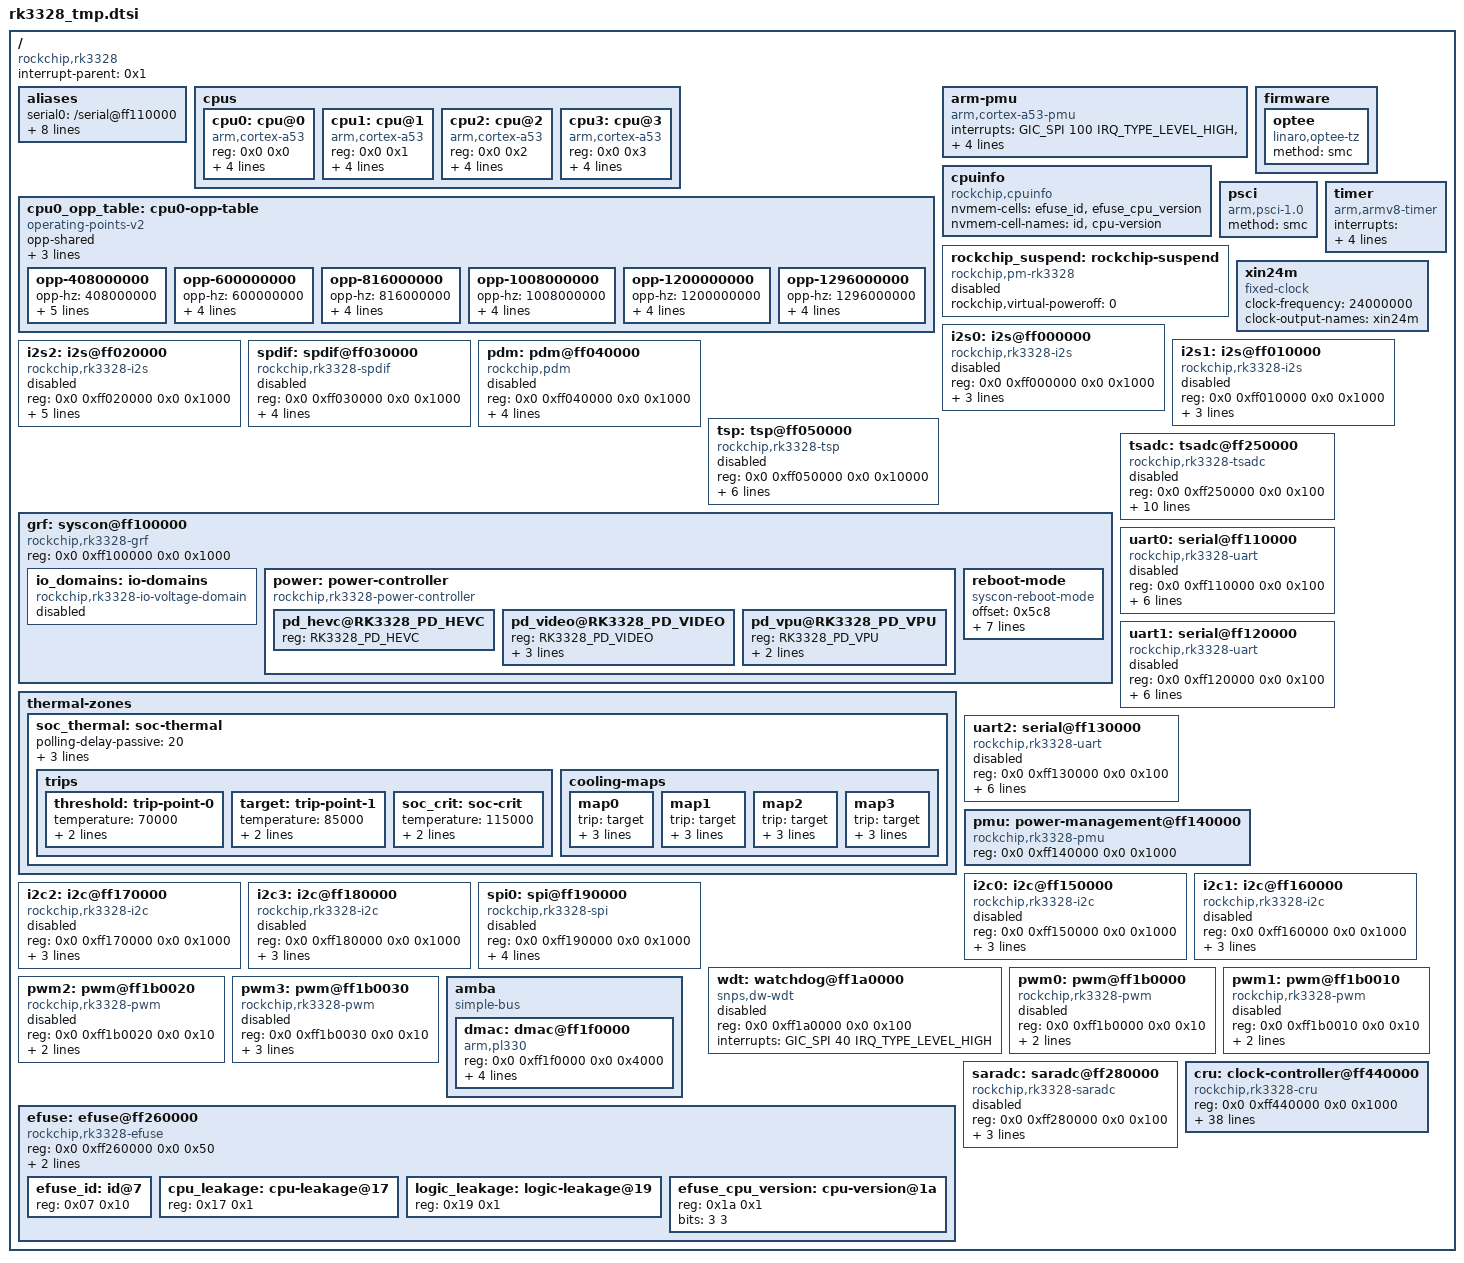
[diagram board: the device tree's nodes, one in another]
/*
 * Copyright (c) 2016 Fuzhou Rockchip Electronics Co., Ltd
 *
 * This file is dual-licensed: you can use it either under the terms
 * of the GPL or the X11 license, at your option. Note that this dual
 * licensing only applies to this file, and not this project as a
 * whole.
 *
 *  a) This library is free software; you can redistribute it and/or
 *     modify it under the terms of the GNU General Public License as
 *     published by the Free Software Foundation; either version 2 of the
 *     License, or (at your option) any later version.
 *
 *     This library is distributed in the hope that it will be useful,
 *     but WITHOUT ANY WARRANTY; without even the implied warranty of
 *     MERCHANTABILITY or FITNESS FOR A PARTICULAR PURPOSE.  See the
 *     GNU General Public License for more details.
 *
 * Or, alternatively,
 *
 *  b) Permission is hereby granted, free of charge, to any person
 *     obtaining a copy of this software and associated documentation
 *     files (the "Software"), to deal in the Software without
 *     restriction, including without limitation the rights to use,
 *     copy, modify, merge, publish, distribute, sublicense, and/or
 *     sell copies of the Software, and to permit persons to whom the
 *     Software is furnished to do so, subject to the following
 *     conditions:
 *
 *     The above copyright notice and this permission notice shall be
 *     included in all copies or substantial portions of the Software.
 *
 *     THE SOFTWARE IS PROVIDED "AS IS", WITHOUT WARRANTY OF ANY KIND,
 *     EXPRESS OR IMPLIED, INCLUDING BUT NOT LIMITED TO THE WARRANTIES
 *     OF MERCHANTABILITY, FITNESS FOR A PARTICULAR PURPOSE AND
 *     NONINFRINGEMENT. IN NO EVENT SHALL THE AUTHORS OR COPYRIGHT
 *     HOLDERS BE LIABLE FOR ANY CLAIM, DAMAGES OR OTHER LIABILITY,
 *     WHETHER IN AN ACTION OF CONTRACT, TORT OR OTHERWISE, ARISING
 *     FROM, OUT OF OR IN CONNECTION WITH THE SOFTWARE OR THE USE OR
 *     OTHER DEALINGS IN THE SOFTWARE.
 */

#include <dt-bindings/clock/rk3328-cru.h>
#include <dt-bindings/gpio/gpio.h>
#include <dt-bindings/interrupt-controller/arm-gic.h>
#include <dt-bindings/interrupt-controller/irq.h>
#include <dt-bindings/pinctrl/rockchip.h>
#include <dt-bindings/soc/rockchip,boot-mode.h>
#include <dt-bindings/soc/rockchip-system-status.h>
#include <dt-bindings/power/rk3328-power.h>
#include <dt-bindings/thermal/thermal.h>
#include "rk3328-dram-default-timing.dtsi"

/ {
	compatible = "rockchip,rk3328";

	interrupt-parent = <0x1>;	//<&gic>;
	#address-cells = <2>;
	#size-cells = <2>;

	aliases {
		serial0 = "/serial@ff110000";		//&uart0;
		serial1 = "/serial@ff120000";		//&uart1;
		serial2 = "/serial@ff130000";		//&uart2;
		i2c0 = "/i2c@ff150000";			//&i2c0;
		i2c1 = "/i2c@ff160000";			//&i2c1;
		i2c2 = "/i2c@ff170000";			//&i2c2;
		i2c3 = "/i2c@ff180000";			//&i2c3;
		ethernet0 = "/ethernet@ff540000";	//&gmac2io;
		ethernet1 = "/ethernet@ff550000";	//&gmac2phy;
	};

	cpus {
		#address-cells = <2>;
		#size-cells = <0>;

		cpu0: cpu@0 {
			device_type = "cpu";
			compatible = "arm,cortex-a53", "arm,armv8";
			reg = <0x0 0x0>;
			enable-method = "psci";
			clocks = <&cru ARMCLK>;
			#cooling-cells = <2>; /* min followed by max */
			dynamic-power-coefficient = <120>;
			operating-points-v2 = <&cpu0_opp_table>;
		};
		cpu1: cpu@1 {
			device_type = "cpu";
			compatible = "arm,cortex-a53", "arm,armv8";
			reg = <0x0 0x1>;
			clocks = <&cru ARMCLK>;
			dynamic-power-coefficient = <120>;
			enable-method = "psci";
			operating-points-v2 = <&cpu0_opp_table>;
		};
		cpu2: cpu@2 {
			device_type = "cpu";
			compatible = "arm,cortex-a53", "arm,armv8";
			reg = <0x0 0x2>;
			clocks = <&cru ARMCLK>;
			dynamic-power-coefficient = <120>;
			enable-method = "psci";
			operating-points-v2 = <&cpu0_opp_table>;
		};
		cpu3: cpu@3 {
			device_type = "cpu";
			compatible = "arm,cortex-a53", "arm,armv8";
			reg = <0x0 0x3>;
			clocks = <&cru ARMCLK>;
			dynamic-power-coefficient = <120>;
			enable-method = "psci";
			operating-points-v2 = <&cpu0_opp_table>;
		};
	};
	
	cpu0_opp_table: cpu0-opp-table {
		compatible = "operating-points-v2";
		opp-shared;

		rockchip,leakage-voltage-sel = <
			1   10    0
			11  254   1
		>;
		nvmem-cells = <&cpu_leakage>;
		nvmem-cell-names = "cpu_leakage";

		opp-408000000 {
			opp-hz = /bits/ 64 <408000000>;
			opp-microvolt = <950000 950000 1350000>;
			opp-microvolt-L0 = <950000 950000 1350000>;
			opp-microvolt-L1 = <950000 950000 1350000>;
			clock-latency-ns = <40000>;
			opp-suspend;
		};
		opp-600000000 {
			opp-hz = /bits/ 64 <600000000>;
			opp-microvolt = <950000 950000 1350000>;
			opp-microvolt-L0 = <950000 950000 1350000>;
			opp-microvolt-L1 = <950000 950000 1350000>;
			clock-latency-ns = <40000>;
		};
		opp-816000000 {
			opp-hz = /bits/ 64 <816000000>;
			opp-microvolt = <1050000 1050000 1350000>;
			opp-microvolt-L0 = <1050000 1050000 1350000>;
			opp-microvolt-L1 = <1000000 1000000 1350000>;
			clock-latency-ns = <40000>;
		};
		opp-1008000000 {
			opp-hz = /bits/ 64 <1008000000>;
			opp-microvolt = <1150000 1150000 1350000>;
			opp-microvolt-L0 = <1150000 1150000 1350000>;
			opp-microvolt-L1 = <1100000 1100000 1350000>;
			clock-latency-ns = <40000>;
		};
		opp-1200000000 {
			opp-hz = /bits/ 64 <1200000000>;
			opp-microvolt = <1275000 1275000 1350000>;
			opp-microvolt-L0 = <1275000 1275000 1350000>;
			opp-microvolt-L1 = <1225000 1225000 1350000>;
			clock-latency-ns = <40000>;
		};
		opp-1296000000 {
			opp-hz = /bits/ 64 <1296000000>;
			opp-microvolt = <1350000 1350000 1350000>;
			opp-microvolt-L0 = <1350000 1350000 1350000>;
			opp-microvolt-L1 = <1300000 1300000 1350000>;
			clock-latency-ns = <40000>;
		};
		/*
		opp-1392000000 {
			opp-hz = /bits/ 64 <1392000000>;
			opp-microvolt = <1350000 1350000 1350000>;
			opp-microvolt-L0 = <1350000 1350000 1350000>;
			opp-microvolt-L1 = <1325000 1325000 1350000>;
			clock-latency-ns = <40000>;
		};
		opp-1512000000 {
			opp-hz = /bits/ 64 <1512000000>;
			opp-microvolt = <1350000 1350000 1350000>;
			opp-microvolt-L0 = <1350000 1350000 1350000>;
			opp-microvolt-L1 = <1325000 1325000 1350000>;
			clock-latency-ns = <40000>;
		};
		*/
	};
	
	arm-pmu {
		compatible = "arm,cortex-a53-pmu";
		interrupts = <GIC_SPI 100 IRQ_TYPE_LEVEL_HIGH>,
			     <GIC_SPI 101 IRQ_TYPE_LEVEL_HIGH>,
			     <GIC_SPI 102 IRQ_TYPE_LEVEL_HIGH>,
			     <GIC_SPI 103 IRQ_TYPE_LEVEL_HIGH>;
		interrupt-affinity = <&cpu0>, <&cpu1>, <&cpu2>, <&cpu3>;
	};

	cpuinfo {
		compatible = "rockchip,cpuinfo";
		nvmem-cells = <&efuse_id>, <&efuse_cpu_version>;
		nvmem-cell-names = "id", "cpu-version";
	};

	firmware {
		optee {
			compatible = "linaro,optee-tz";
			method = "smc";
		};
	};

	psci {
		compatible = "arm,psci-1.0";
		method = "smc";
	};

	rockchip_suspend: rockchip-suspend {
		compatible = "rockchip,pm-rk3328";
		status = "disabled";
		rockchip,virtual-poweroff = <0>;
	};

	timer {
		compatible = "arm,armv8-timer";
		interrupts = <GIC_PPI 13 (GIC_CPU_MASK_SIMPLE(4) | IRQ_TYPE_LEVEL_LOW)>,
			     <GIC_PPI 14 (GIC_CPU_MASK_SIMPLE(4) | IRQ_TYPE_LEVEL_LOW)>,
			     <GIC_PPI 11 (GIC_CPU_MASK_SIMPLE(4) | IRQ_TYPE_LEVEL_LOW)>,
			     <GIC_PPI 10 (GIC_CPU_MASK_SIMPLE(4) | IRQ_TYPE_LEVEL_LOW)>;
	};

	xin24m: xin24m {
		compatible = "fixed-clock";
		#clock-cells = <0>;
		clock-frequency = <24000000>;
		clock-output-names = "xin24m";
	};

	i2s0: i2s@ff000000 {
		compatible = "rockchip,rk3328-i2s", "rockchip,rk3066-i2s";
		reg = <0x0 0xff000000 0x0 0x1000>;
		interrupts = <GIC_SPI 26 IRQ_TYPE_LEVEL_HIGH>;
		clocks = <&cru SCLK_I2S0>, <&cru HCLK_I2S0_8CH>;
		clock-names = "i2s_clk", "i2s_hclk";
		dmas = <&dmac 11>, <&dmac 12>;
		dma-names = "tx", "rx";
		status = "disabled";
	};

	i2s1: i2s@ff010000 {
		compatible = "rockchip,rk3328-i2s", "rockchip,rk3066-i2s";
		reg = <0x0 0xff010000 0x0 0x1000>;
		interrupts = <GIC_SPI 27 IRQ_TYPE_LEVEL_HIGH>;
		clocks = <&cru SCLK_I2S1>, <&cru HCLK_I2S1_8CH>;
		clock-names = "i2s_clk", "i2s_hclk";
		dmas = <&dmac 14>, <&dmac 15>;
		dma-names = "tx", "rx";
		status = "disabled";
	};

	i2s2: i2s@ff020000 {
		compatible = "rockchip,rk3328-i2s", "rockchip,rk3066-i2s";
		reg = <0x0 0xff020000 0x0 0x1000>;
		interrupts = <GIC_SPI 28 IRQ_TYPE_LEVEL_HIGH>;
		clocks = <&cru SCLK_I2S2>, <&cru HCLK_I2S2_2CH>;
		clock-names = "i2s_clk", "i2s_hclk";
		dmas = <&dmac 0>, <&dmac 1>;
		dma-names = "tx", "rx";
		pinctrl-names = "default", "sleep";
		pinctrl-0 = <0xd 0xe 0xf 0x10 0x11 0x12>;	/*<&i2s2m0_mclk
			     &i2s2m0_sclk
			     &i2s2m0_lrcktx
			     &i2s2m0_lrckrx
			     &i2s2m0_sdo
			     &i2s2m0_sdi>;*/
		pinctrl-1 = <0x13>;				//<&i2s2m0_sleep>;
		status = "disabled";
	};

	spdif: spdif@ff030000 {
		compatible = "rockchip,rk3328-spdif";
		reg = <0x0 0xff030000 0x0 0x1000>;
		interrupts = <GIC_SPI 29 IRQ_TYPE_LEVEL_HIGH>;
		clocks = <&cru SCLK_SPDIF>, <&cru HCLK_SPDIF_8CH>;
		clock-names = "mclk", "hclk";
		dmas = <&dmac 10>;
		dma-names = "tx";
		pinctrl-names = "default";
		pinctrl-0 = <0x14>;				//<&spdifm2_tx>;
		status = "disabled";
	};

	pdm: pdm@ff040000 {
		compatible = "rockchip,pdm";
		reg = <0x0 0xff040000 0x0 0x1000>;
		clocks = <&cru SCLK_PDM>, <&cru HCLK_PDM>;
		clock-names = "pdm_clk", "pdm_hclk";
		dmas = <&dmac 16>;
		dma-names = "rx";
		pinctrl-names = "default", "sleep";
		pinctrl-0 = <0x15 0x16 0x17 0x18 0x19 0x1a>;
		pinctrl-1 = <0x1b>;
		/*pinctrl-0 = <&pdmm0_clk
			     &pdmm0_fsync
			     &pdmm0_sdi0
			     &pdmm0_sdi1
			     &pdmm0_sdi2
			     &pdmm0_sdi3>;
		pinctrl-1 = <&pdmm0_sleep>;*/
		status = "disabled";
	};

	tsp: tsp@ff050000 {
		compatible = "rockchip,rk3328-tsp";
		reg = <0x0 0xff050000 0x0 0x10000>;
		rockchip,grf = <&grf>;
		interrupts = <GIC_SPI 72 IRQ_TYPE_LEVEL_HIGH>;
		interrupt-names = "irq_tsp";
		clocks = <&cru SCLK_TSP>, <&cru ACLK_TSP>, <&cru HCLK_TSP>;
		clock-names = "clk_tsp", "aclk_tsp", "hclk_tsp";
		pinctrl-names = "default";
		pinctrl-0 = <0x1d 0x1e 0x1f 0x20 0x21 0x22 0x23 0x24 0x25 0x26 0x27 0x28>;
		/*pinctrl-0 = <&tsp_d0
			     &tsp_d1
			     &tsp_d2
			     &tsp_d3
			     &tsp_d4
			     &tsp_d5
			     &tsp_d6
			     &tsp_d7
			     &tsp_sync
			     &tsp_clk
			     &tsp_fail
			     &tsp_valid>;*/
		status = "disabled";
	};

	grf: syscon@ff100000 {
		compatible = "rockchip,rk3328-grf", "syscon", "simple-mfd";
		reg = <0x0 0xff100000 0x0 0x1000>;
		#address-cells = <1>;
		#size-cells = <1>;

		io_domains: io-domains {
			compatible = "rockchip,rk3328-io-voltage-domain";
			status = "disabled";
		};

		power: power-controller {
			compatible = "rockchip,rk3328-power-controller";
			#power-domain-cells = <1>;
			#address-cells = <1>;
			#size-cells = <0>;
			status = "okay";

			pd_hevc@RK3328_PD_HEVC {
				reg = <RK3328_PD_HEVC>;
			};
			pd_video@RK3328_PD_VIDEO {
				reg = <RK3328_PD_VIDEO>;
				clocks = <&cru ACLK_RKVDEC>,
					 <&cru HCLK_RKVDEC>,
					 <&cru SCLK_VDEC_CABAC>,
					 <&cru SCLK_VDEC_CORE>;
				pm_qos = <0x2c 0x2d>;			//<&qos_rkvdec_r>, <&qos_rkvdec_w>;
			};
			pd_vpu@RK3328_PD_VPU {
				reg = <RK3328_PD_VPU>;
				clocks = <&cru ACLK_VPU>,
					 <&cru HCLK_VPU>;
				pm_qos = <0x2e>;			//<&qos_vpu>;
			};
		};

		reboot-mode {
			compatible = "syscon-reboot-mode";
			offset = <0x5c8>;
			mode-bootloader = <BOOT_BL_DOWNLOAD>;
			mode-charge = <BOOT_CHARGING>;
			mode-fastboot = <BOOT_FASTBOOT>;
			mode-loader = <BOOT_BL_DOWNLOAD>;
			mode-normal = <BOOT_NORMAL>;
			mode-recovery = <BOOT_RECOVERY>;
			mode-ums = <BOOT_UMS>;
		};
	};

	thermal-zones {
		soc_thermal: soc-thermal {
			polling-delay-passive = <20>; /* milliseconds */
			polling-delay = <1000>; /* milliseconds */
			sustainable-power = <1000>; /* milliwatts */

			thermal-sensors = <&tsadc 0>;

			trips {
				threshold: trip-point-0 {
					temperature = <70000>; /* millicelsius */
					hysteresis = <2000>; /* millicelsius */
					type = "passive";
				};
				target: trip-point-1 {
					temperature = <85000>; /* millicelsius */
					hysteresis = <2000>; /* millicelsius */
					type = "passive";
				};
				soc_crit: soc-crit {
					temperature = <115000>; /* millicelsius */
					hysteresis = <2000>; /* millicelsius */
					type = "critical";
				};
			};

			cooling-maps {
				map0 {
					trip = <&target>;
					cooling-device = <&cpu0 THERMAL_NO_LIMIT THERMAL_NO_LIMIT>;
					contribution = <4096>;
				};
				map1 {
					trip = <&target>;
					cooling-device = <0x31 THERMAL_NO_LIMIT THERMAL_NO_LIMIT>;	//&gpu
					contribution = <4096>;
				};
				map2 {
					trip = <&target>;
					cooling-device = <0x32 THERMAL_NO_LIMIT THERMAL_NO_LIMIT>;		//&rkvdec
					contribution = <1024>;
				};
				map3 {
					trip = <&target>;
					cooling-device = <0x33 THERMAL_NO_LIMIT THERMAL_NO_LIMIT>;		//&dmc
					contribution = <1024>;
				};
			};
		};

	};

	tsadc: tsadc@ff250000 {
		compatible = "rockchip,rk3328-tsadc";
		reg = <0x0 0xff250000 0x0 0x100>;
		interrupts = <GIC_SPI 58 IRQ_TYPE_LEVEL_HIGH>;
		rockchip,grf = <&grf>;
		clocks = <&cru SCLK_TSADC>, <&cru PCLK_TSADC>;
		clock-names = "tsadc", "apb_pclk";
		assigned-clocks = <&cru SCLK_TSADC>;
		assigned-clock-rates = <50000>;
		resets = <&cru SRST_TSADC>;
		reset-names = "tsadc-apb";
		pinctrl-names = "init", "default", "sleep";
		pinctrl-0 = <0x34>;
		pinctrl-1 = <0x35>;
		pinctrl-2 = <0x34>;
		/*pinctrl-0 = <&otp_gpio>;
		pinctrl-1 = <&otp_out>;
		pinctrl-2 = <&otp_gpio>;*/
		#thermal-sensor-cells = <1>;
		rockchip,hw-tshut-temp = <120000>;
		status = "disabled";
	};

	uart0: serial@ff110000 {
		compatible = "rockchip,rk3328-uart", "snps,dw-apb-uart";
		reg = <0x0 0xff110000 0x0 0x100>;
		interrupts = <GIC_SPI 55 IRQ_TYPE_LEVEL_HIGH>;
		clocks = <&cru SCLK_UART0>, <&cru PCLK_UART0>;
		clock-names = "baudclk", "apb_pclk";
		reg-shift = <2>;
		reg-io-width = <4>;
		dmas = <&dmac 2>, <&dmac 3>;
		dma-names = "tx", "rx";
		pinctrl-names = "default";
		pinctrl-0 = <0x36 0x37>;
		//pinctrl-0 = <&uart0_xfer &uart0_cts &uart0_rts>;
		status = "disabled";
	};

	uart1: serial@ff120000 {
		compatible = "rockchip,rk3328-uart", "snps,dw-apb-uart";
		reg = <0x0 0xff120000 0x0 0x100>;
		interrupts = <GIC_SPI 56 IRQ_TYPE_LEVEL_HIGH>;
		clocks = <&cru SCLK_UART1>, <&cru PCLK_UART1>;
		clock-names = "baudclk", "apb_pclk";
		reg-shift = <2>;
		reg-io-width = <4>;
		dmas = <&dmac 4>, <&dmac 5>;
		dma-names = "tx", "rx";
		pinctrl-names = "default";
		pinctrl-0 = <0x38 0x39 0x3a>;			//pinctrl-0 = <&uart1_xfer &uart1_cts &uart1_rts>;
		status = "disabled";
	};

	uart2: serial@ff130000 {
		compatible = "rockchip,rk3328-uart", "snps,dw-apb-uart";
		reg = <0x0 0xff130000 0x0 0x100>;
		interrupts = <GIC_SPI 57 IRQ_TYPE_LEVEL_HIGH>;
		clocks = <&cru SCLK_UART2>, <&cru PCLK_UART2>;
		clock-names = "baudclk", "apb_pclk";
		reg-shift = <2>;
		reg-io-width = <4>;
		dmas = <&dmac 6>, <&dmac 7>;
		dma-names = "tx", "rx";
		pinctrl-names = "default";
		pinctrl-0 = <0x3b>;				//pinctrl-0 = <&uart2m1_xfer>;
		status = "disabled";
	};

	pmu: power-management@ff140000 {
		compatible = "rockchip,rk3328-pmu", "syscon", "simple-mfd";
		reg = <0x0 0xff140000 0x0 0x1000>;
	};

	i2c0: i2c@ff150000 {
		compatible = "rockchip,rk3328-i2c", "rockchip,rk3399-i2c";
		reg = <0x0 0xff150000 0x0 0x1000>;
		interrupts = <GIC_SPI 36 IRQ_TYPE_LEVEL_HIGH>;
		#address-cells = <1>;
		#size-cells = <0>;
		clocks = <&cru SCLK_I2C0>, <&cru PCLK_I2C0>;
		clock-names = "i2c", "pclk";
		pinctrl-names = "default";
		pinctrl-0 = <0x3c>;			//pinctrl-0 = <&i2c0_xfer>;
		status = "disabled";
	};

	i2c1: i2c@ff160000 {
		compatible = "rockchip,rk3328-i2c", "rockchip,rk3399-i2c";
		reg = <0x0 0xff160000 0x0 0x1000>;
		interrupts = <GIC_SPI 37 IRQ_TYPE_LEVEL_HIGH>;
		#address-cells = <1>;
		#size-cells = <0>;
		clocks = <&cru SCLK_I2C1>, <&cru PCLK_I2C1>;
		clock-names = "i2c", "pclk";
		pinctrl-names = "default";
		pinctrl-0 = <0x3d>;			//pinctrl-0 = <&i2c1_xfer>;
		status = "disabled";
	};

	i2c2: i2c@ff170000 {
		compatible = "rockchip,rk3328-i2c", "rockchip,rk3399-i2c";
		reg = <0x0 0xff170000 0x0 0x1000>;
		interrupts = <GIC_SPI 38 IRQ_TYPE_LEVEL_HIGH>;
		#address-cells = <1>;
		#size-cells = <0>;
		clocks = <&cru SCLK_I2C2>, <&cru PCLK_I2C2>;
		clock-names = "i2c", "pclk";
		pinctrl-names = "default";
		pinctrl-0 = <0x40>;			//pinctrl-0 = <&i2c2_xfer>;
		status = "disabled";
	};

	i2c3: i2c@ff180000 {
		compatible = "rockchip,rk3328-i2c", "rockchip,rk3399-i2c";
		reg = <0x0 0xff180000 0x0 0x1000>;
		interrupts = <GIC_SPI 39 IRQ_TYPE_LEVEL_HIGH>;
		#address-cells = <1>;
		#size-cells = <0>;
		clocks = <&cru SCLK_I2C3>, <&cru PCLK_I2C3>;
		clock-names = "i2c", "pclk";
		pinctrl-names = "default";
		pinctrl-0 = <0x41>;			//pinctrl-0 = <&i2c3_xfer>;
		status = "disabled";
	};

	spi0: spi@ff190000 {
		compatible = "rockchip,rk3328-spi", "rockchip,rk3066-spi";
		reg = <0x0 0xff190000 0x0 0x1000>;
		interrupts = <GIC_SPI 49 IRQ_TYPE_LEVEL_HIGH>;
		#address-cells = <1>;
		#size-cells = <0>;
		clocks = <&cru SCLK_SPI>, <&cru PCLK_SPI>;
		clock-names = "spiclk", "apb_pclk";
		dmas = <&dmac 8>, <&dmac 9>;
		dma-names = "tx", "rx";
		pinctrl-names = "default";
		pinctrl-0 = <0x42 0x43 0x44 0x45>;	//pinctrl-0 = <&spi0m2_clk &spi0m2_tx &spi0m2_rx &spi0m2_cs0>;
		status = "disabled";
	};

	wdt: watchdog@ff1a0000 {
		compatible = "snps,dw-wdt";
		reg = <0x0 0xff1a0000 0x0 0x100>;
		interrupts = <GIC_SPI 40 IRQ_TYPE_LEVEL_HIGH>;
		status = "disabled";
	};
	
	pwm0: pwm@ff1b0000 {
		compatible = "rockchip,rk3328-pwm";
		reg = <0x0 0xff1b0000 0x0 0x10>;
		#pwm-cells = <3>;
		pinctrl-names = "active";
		pinctrl-0 = <0x46>;			//pinctrl-0 = <&pwm0_pin>;
		clocks = <&cru SCLK_PWM>, <&cru PCLK_PWM>;
		clock-names = "pwm", "pclk";
		status = "disabled";
	};

	pwm1: pwm@ff1b0010 {
		compatible = "rockchip,rk3328-pwm";
		reg = <0x0 0xff1b0010 0x0 0x10>;
		#pwm-cells = <3>;
		pinctrl-names = "active";
		pinctrl-0 = <0x47>;			//pinctrl-0 = <&pwm1_pin>;
		clocks = <&cru SCLK_PWM>, <&cru PCLK_PWM>;
		clock-names = "pwm", "pclk";
		status = "disabled";
	};

	pwm2: pwm@ff1b0020 {
		compatible = "rockchip,rk3328-pwm";
		reg = <0x0 0xff1b0020 0x0 0x10>;
		#pwm-cells = <3>;
		pinctrl-names = "active";
		pinctrl-0 = <0x48>;			//pinctrl-0 = <&pwm2_pin>;
		clocks = <&cru SCLK_PWM>, <&cru PCLK_PWM>;
		clock-names = "pwm", "pclk";
		status = "disabled";
	};

	pwm3: pwm@ff1b0030 {
		compatible = "rockchip,rk3328-pwm";
		reg = <0x0 0xff1b0030 0x0 0x10>;
		interrupts = <GIC_SPI 50 IRQ_TYPE_LEVEL_HIGH>;
		#pwm-cells = <3>;
		pinctrl-names = "active";
		pinctrl-0 = <0x49>;			//pinctrl-0 = <&pwmir_pin>;
		clocks = <&cru SCLK_PWM>, <&cru PCLK_PWM>;
		clock-names = "pwm", "pclk";
		status = "disabled";
	};

	amba {
		compatible = "simple-bus";
		#address-cells = <2>;
		#size-cells = <2>;
		ranges;

		dmac: dmac@ff1f0000 {
			compatible = "arm,pl330", "arm,primecell";
			reg = <0x0 0xff1f0000 0x0 0x4000>;
			interrupts = <GIC_SPI 0 IRQ_TYPE_LEVEL_HIGH>,
				     <GIC_SPI 1 IRQ_TYPE_LEVEL_HIGH>;
			clocks = <&cru ACLK_DMAC>;
			clock-names = "apb_pclk";
			#dma-cells = <1>;
			peripherals-req-type-burst;
		};
	};

	efuse: efuse@ff260000 {
		compatible = "rockchip,rk3328-efuse";
		reg = <0x0 0xff260000 0x0 0x50>;
		#address-cells = <1>;
		#size-cells = <1>;
		clocks = <&cru SCLK_EFUSE>;
		clock-names = "pclk_efuse";
		rockchip,efuse-size = <0x20>;

		/* Data cells */
		efuse_id: id@7 {
			reg = <0x07 0x10>;
		};
		cpu_leakage: cpu-leakage@17 {
			reg = <0x17 0x1>;
		};
		logic_leakage: logic-leakage@19 {
			reg = <0x19 0x1>;
		};
		efuse_cpu_version: cpu-version@1a {
			reg = <0x1a 0x1>;
			bits = <3 3>;
		};
	};

	saradc: saradc@ff280000 {
		compatible = "rockchip,rk3328-saradc", "rockchip,rk3399-saradc";
		reg = <0x0 0xff280000 0x0 0x100>;
		interrupts = <GIC_SPI 80 IRQ_TYPE_LEVEL_HIGH>;
		#io-channel-cells = <1>;
		clocks = <&cru SCLK_SARADC>, <&cru PCLK_SARADC>;
		clock-names = "saradc", "apb_pclk";
		resets = <&cru SRST_SARADC_P>;
		reset-names = "saradc-apb";
		status = "disabled";
	};

	
	
	cru: clock-controller@ff440000 {
		compatible = "rockchip,rk3328-cru", "rockchip,cru", "syscon";
		reg = <0x0 0xff440000 0x0 0x1000>;
		rockchip,grf = <0x1c>;				//<&grf>;
		#clock-cells = <1>;
		#reset-cells = <1>;
		assigned-clocks =
			<&cru DCLK_LCDC>, <&cru SCLK_PDM>,
			<&cru SCLK_RTC32K>, <&cru SCLK_UART0>,
			<&cru SCLK_UART1>, <&cru SCLK_UART2>,
			<&cru ACLK_BUS_PRE>, <&cru ACLK_PERI_PRE>,
			<&cru ACLK_RGA_PRE>, <&cru ACLK_RKVDEC_PRE>,
			<&cru ACLK_RKVENC>, <&cru ACLK_VPU_PRE>,
			<&cru SCLK_VDEC_CABAC>, <&cru SCLK_VDEC_CORE>,
			<&cru SCLK_VENC_CORE>, <&cru SCLK_VENC_DSP>,
			<&cru SCLK_SDIO>, <&cru SCLK_TSP>,
			<&cru SCLK_WIFI>, <&cru ARMCLK>,
			<&cru PLL_GPLL>, <&cru PLL_CPLL>,
			<&cru ACLK_BUS_PRE>, <&cru HCLK_BUS_PRE>,
			<&cru PCLK_BUS_PRE>, <&cru ACLK_PERI_PRE>,
			<&cru HCLK_PERI>, <&cru PCLK_PERI>,
			<&cru ACLK_VIO_PRE>, <&cru HCLK_VIO_PRE>,
			<&cru ACLK_RGA_PRE>, <&cru SCLK_RGA>,
			<&cru ACLK_VOP_PRE>, <&cru ACLK_RKVDEC_PRE>,
			<&cru ACLK_RKVENC>, <&cru ACLK_VPU_PRE>,
			<&cru SCLK_VDEC_CABAC>, <&cru SCLK_VDEC_CORE>,
			<&cru SCLK_VENC_CORE>, <&cru SCLK_VENC_DSP>,
			<&cru SCLK_EFUSE>, <&cru PCLK_DDR>,
			<&cru ACLK_GMAC>, <&cru PCLK_GMAC>,
			<&cru SCLK_RTC32K>, <&cru SCLK_USB3OTG_SUSPEND>;
		assigned-clock-parents =
			<&cru HDMIPHY>, <&cru PLL_APLL>,
			<&cru PLL_GPLL>, <&xin24m>,
			<&xin24m>, <&xin24m>;
		assigned-clock-rates =
			<0>, <61440000>,
			<0>, <24000000>,
			<24000000>, <24000000>,
			<15000000>, <15000000>,
			<100000000>, <100000000>,
			<50000000>, <100000000>,
			<100000000>, <100000000>,
			<50000000>, <50000000>,
			<50000000>, <50000000>,
			<24000000>, <600000000>,
			<491520000>, <1200000000>,
			<150000000>, <75000000>,
			<75000000>, <150000000>,
			<75000000>, <75000000>,
			<300000000>, <100000000>,
			<300000000>, <200000000>,
			<400000000>, <500000000>,
			<200000000>, <300000000>,
			<300000000>, <250000000>,
			<200000000>, <100000000>,
			<24000000>, <100000000>,
			<150000000>, <50000000>,
			<32768>, <32768>;
	};
};
